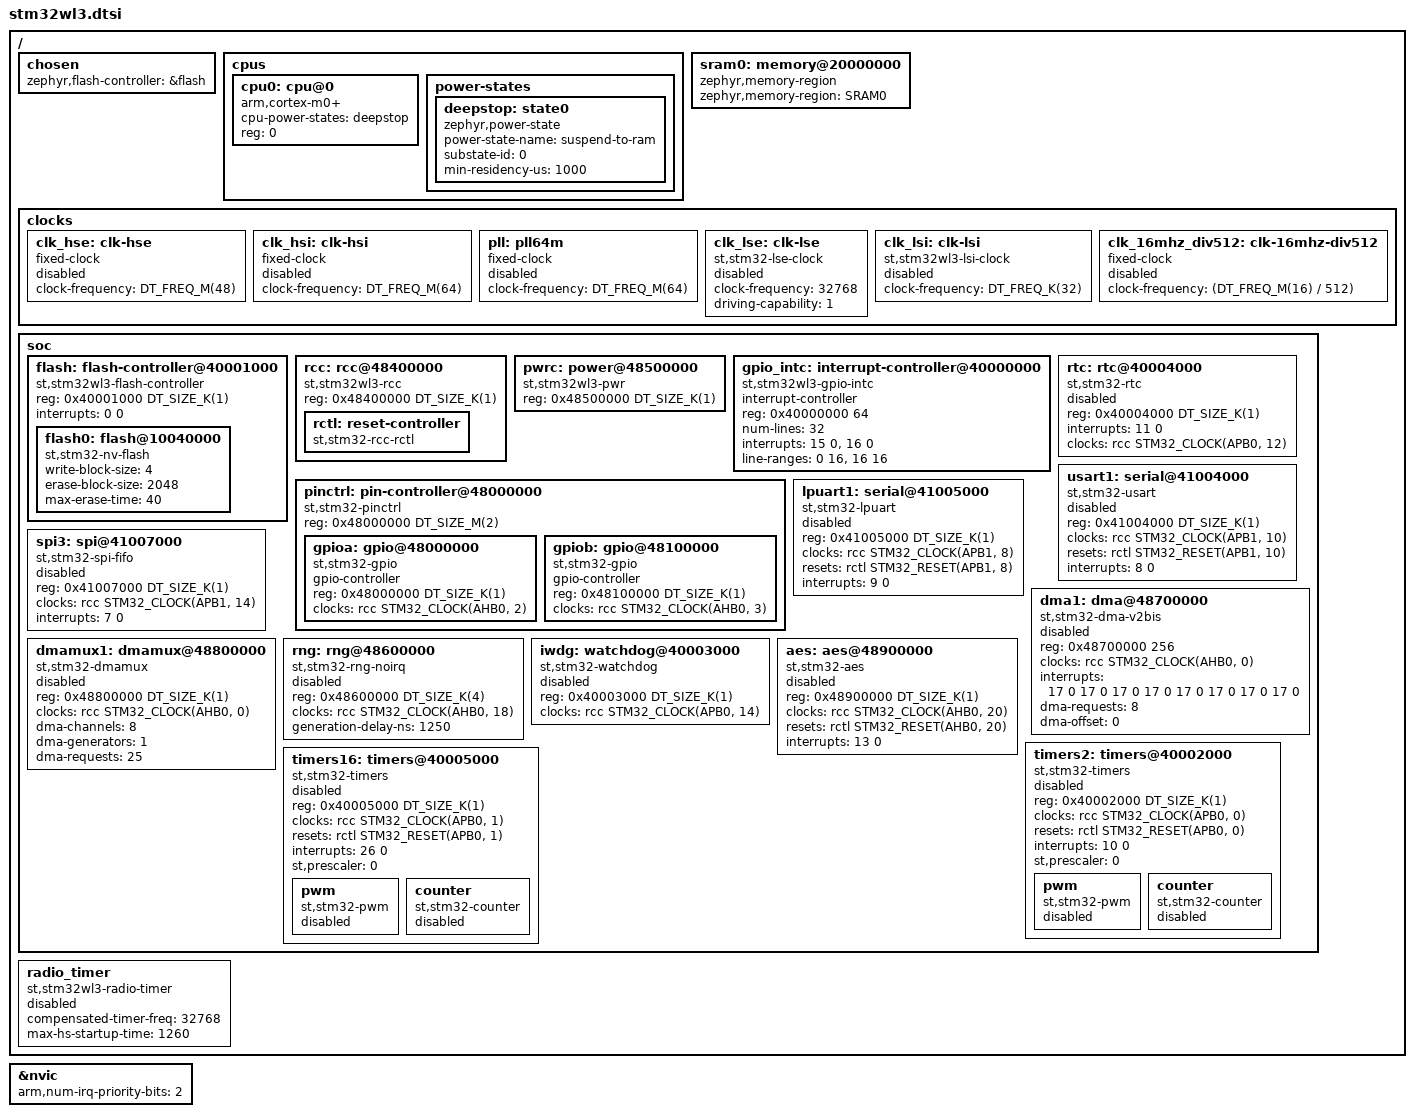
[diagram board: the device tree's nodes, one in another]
/*
 * Copyright (c) 2024 STMicroelectronics
 * Copyright (c) 2026 Movu robotics
 *
 * SPDX-License-Identifier: Apache-2.0
 */

#include <arm/armv6-m.dtsi>
#include <zephyr/dt-bindings/i2c/i2c.h>
#include <zephyr/dt-bindings/adc/adc.h>
#include <zephyr/dt-bindings/pwm/pwm.h>
#include <zephyr/dt-bindings/gpio/gpio.h>
#include <zephyr/dt-bindings/clock/stm32wl3_clock.h>
#include <zephyr/dt-bindings/reset/stm32wl3_reset.h>
#include <zephyr/dt-bindings/dma/stm32_dma.h>
#include <freq.h>
#include <mem.h>

/* NOTE: for some registers, the reserved size in the memory map differs
 * between WL30 and WB31/33. In these cases, if all the registers fit
 * in the smallest size, the peripheral is defined in this file with the
 * smallest size in the 'reg' property.
 */
/ {
	chosen {
		zephyr,flash-controller = &flash;
	};

	cpus {
		#address-cells = <1>;
		#size-cells = <0>;

		cpu0: cpu@0 {
			device_type = "cpu";
			compatible = "arm,cortex-m0+";
			cpu-power-states = <&deepstop>;
			reg = <0>;
		};

		power-states {
			deepstop: state0 {
				compatible = "zephyr,power-state";
				power-state-name = "suspend-to-ram";
				substate-id = <0>;

				/* One millisecond seems reasonable for now. */
				min-residency-us = <1000>;

				/* exit-latency-us property is not needed
				 * since the same concept is applied by the hardware automatically.
				 */
			};
		};
	};

	sram0: memory@20000000 {
		compatible = "zephyr,memory-region", "mmio-sram";
		zephyr,memory-region = "SRAM0";
	};

	clocks {
		/* High-speed clock nodes
		 * These nodes must only be used as input to
		 * the RCC node (i.e., 'clocks' property)
		 */
		clk_hse: clk-hse {
			#clock-cells = <0>;
			compatible = "fixed-clock";
			clock-frequency = <DT_FREQ_M(48)>;
			status = "disabled";
		};

		clk_hsi: clk-hsi {
			#clock-cells = <0>;
			compatible = "fixed-clock";
			clock-frequency = <DT_FREQ_M(64)>;
			status = "disabled";
		};

		/* Dummy node representing the RC64MPLL block in PLL mode
		 * Using this node as RCC node input requires HSE to be enabled.
		 */
		pll: pll64m {
			#clock-cells = <0>;
			compatible = "fixed-clock";
			clock-frequency = <DT_FREQ_M(64)>;
			status = "disabled";
		};

		/* Slow speed clock nodes
		 * These nodes must only be used for the
		 * 'slow-clock' property of the RCC node.
		 */
		clk_lse: clk-lse {
			#clock-cells = <0>;
			compatible = "st,stm32-lse-clock";
			clock-frequency = <32768>;
			driving-capability = <1>;
			status = "disabled";
		};

		clk_lsi: clk-lsi {
			/* "fixed-clock" compatible is required for compatibility with the
			 * macros in `include/drivers/clock_control/stm32_clock_control.h`
			 */
			#clock-cells = <0>;
			compatible = "st,stm32wl3-lsi-clock", "fixed-clock";
			clock-frequency = <DT_FREQ_K(32)>;
			status = "disabled";
		};

		/* Dummy node representing the "CLK_16MHz/512" slow clock source.
		 * WARNING: this clock is not active in DEEPSTOP, so all slow clock peripherals
		 * are stopped, and cannot wake up the SoC, if this is selected as slow-clock!
		 */
		clk_16mhz_div512: clk-16mhz-div512 {
			#clock-cells = <0>;
			compatible = "fixed-clock";
			clock-frequency = <(DT_FREQ_M(16) / 512)>;
			status = "disabled";
		};
	};

	soc {

		flash: flash-controller@40001000 {
			compatible = "st,stm32wl3-flash-controller", "st,stm32-flash-controller";
			reg = <0x40001000 DT_SIZE_K(1)>;
			interrupts = <0 0>;

			#address-cells = <1>;
			#size-cells = <1>;

			flash0: flash@10040000 {
				compatible = "st,stm32-nv-flash", "soc-nv-flash";
				write-block-size = <4>;
				erase-block-size = <2048>;
				/* maximum erase time(ms) for a page (2K) */
				max-erase-time = <40>;
			};
		};

		rcc: rcc@48400000 {
			compatible = "st,stm32wl3-rcc";
			reg = <0x48400000 DT_SIZE_K(1)>;
			#clock-cells = <2>;

			rctl: reset-controller {
				compatible = "st,stm32-rcc-rctl";
				#reset-cells = <1>;
			};
		};

		pwrc: power@48500000 {
			compatible = "st,stm32wl3-pwr";
			reg = <0x48500000 DT_SIZE_K(1)>;
		};

		/* STM32WL3 GPIO interrupt controller
		 *
		 * The 'reg' property corresponds to the SYSCFG memory range,
		 * because that's where the GPIO INTC registers are located.
		 */
		gpio_intc: interrupt-controller@40000000 {
			compatible = "st,stm32wl3-gpio-intc";
			interrupt-controller;
			#interrupt-cells = <1>;
			#address-cells = <1>;
			reg = <0x40000000 64>;
			num-lines = <32>;
			interrupts = <15 0>, <16 0>;
			interrupt-names = "gpioa", "gpiob";
			line-ranges = <0 16>, <16 16>;
		};

		pinctrl: pin-controller@48000000 {
			compatible = "st,stm32-pinctrl";
			#address-cells = <1>;
			#size-cells = <1>;
			reg = <0x48000000 DT_SIZE_M(2)>;

			gpioa: gpio@48000000 {
				compatible = "st,stm32-gpio";
				gpio-controller;
				#gpio-cells = <2>;
				reg = <0x48000000 DT_SIZE_K(1)>;
				clocks = <&rcc STM32_CLOCK(AHB0, 2)>;
			};

			gpiob: gpio@48100000 {
				compatible = "st,stm32-gpio";
				gpio-controller;
				#gpio-cells = <2>;
				reg = <0x48100000 DT_SIZE_K(1)>;
				clocks = <&rcc STM32_CLOCK(AHB0, 3)>;
			};
		};

		rtc: rtc@40004000 {
			compatible = "st,stm32-rtc";
			reg = <0x40004000 DT_SIZE_K(1)>;
			interrupts = <11 0>;
			clocks = <&rcc STM32_CLOCK(APB0, 12)>;
			status = "disabled";
		};

		usart1: serial@41004000 {
			compatible = "st,stm32-usart", "st,stm32-uart";
			reg = <0x41004000 DT_SIZE_K(1)>;

			clocks = <&rcc STM32_CLOCK(APB1, 10)>;
			resets = <&rctl STM32_RESET(APB1, 10)>;
			interrupts = <8 0>;
			status = "disabled";
		};

		lpuart1: serial@41005000 {
			compatible = "st,stm32-lpuart", "st,stm32-uart";
			reg = <0x41005000 DT_SIZE_K(1)>;
			clocks = <&rcc STM32_CLOCK(APB1, 8)>;
			resets = <&rctl STM32_RESET(APB1, 8)>;
			interrupts = <9 0>;
			status = "disabled";
		};

		spi3: spi@41007000 {
			compatible = "st,stm32-spi-fifo", "st,stm32-spi";
			#address-cells = <1>;
			#size-cells = <0>;
			reg = <0x41007000 DT_SIZE_K(1)>;
			clocks = <&rcc STM32_CLOCK(APB1, 14)>;
			interrupts = <7 0>;
			status = "disabled";
		};

		dma1: dma@48700000 {
			compatible = "st,stm32-dma-v2bis";
			#dma-cells = <2>;
			reg = <0x48700000 256>;
			clocks = <&rcc STM32_CLOCK(AHB0, 0)>;
			interrupts = <17 0 17 0 17 0 17 0 17 0 17 0 17 0 17 0>;
			dma-requests = <8>;
			dma-offset = <0>;
			status = "disabled";
		};

		dmamux1: dmamux@48800000 {
			compatible = "st,stm32-dmamux";
			reg = <0x48800000 DT_SIZE_K(1)>;
			/* `clocks` property is identical between DMA and DMAMUX
			 * because they share a single common bit in RCC registers
			 */
			clocks = <&rcc STM32_CLOCK(AHB0, 0)>;
			#dma-cells = <3>;
			dma-channels = <8>;
			dma-generators = <1>;
			dma-requests = <25>;
			status = "disabled";
		};

		rng: rng@48600000 {
			compatible = "st,stm32-rng-noirq";
			reg = <0x48600000 DT_SIZE_K(4)>;
			clocks = <&rcc STM32_CLOCK(AHB0, 18)>;
			generation-delay-ns = <1250>; /* 1.25us */
			status = "disabled";
		};

		iwdg: watchdog@40003000 {
			compatible = "st,stm32-watchdog";
			reg = <0x40003000 DT_SIZE_K(1)>;
			clocks = <&rcc STM32_CLOCK(APB0, 14)>;
			status = "disabled";
		};

		aes: aes@48900000 {
			compatible = "st,stm32-aes";
			reg = <0x48900000 DT_SIZE_K(1)>;
			clocks = <&rcc STM32_CLOCK(AHB0, 20)>;
			resets = <&rctl STM32_RESET(AHB0, 20)>;
			interrupts = <13 0>;
			status = "disabled";
		};

		timers2: timers@40002000 {
			compatible = "st,stm32-timers";
			reg = <0x40002000 DT_SIZE_K(1)>;
			clocks = <&rcc STM32_CLOCK(APB0, 0)>;
			resets = <&rctl STM32_RESET(APB0, 0)>;
			interrupts = <10 0>;
			interrupt-names = "global";
			st,prescaler = <0>;
			status = "disabled";

			pwm {
				compatible = "st,stm32-pwm";
				status = "disabled";
				#pwm-cells = <3>;
			};

			counter {
				compatible = "st,stm32-counter";
				status = "disabled";
			};
		};

		timers16: timers@40005000 {
			compatible = "st,stm32-timers";
			reg = <0x40005000 DT_SIZE_K(1)>;
			clocks = <&rcc STM32_CLOCK(APB0, 1)>;
			resets = <&rctl STM32_RESET(APB0, 1)>;
			interrupts = <26 0>;
			interrupt-names = "global";
			st,prescaler = <0>;
			status = "disabled";

			pwm {
				compatible = "st,stm32-pwm";
				status = "disabled";
				#pwm-cells = <3>;
			};

			counter {
				compatible = "st,stm32-counter";
				status = "disabled";
			};
		};

	};

	radio_timer: radio_timer {
		compatible = "st,stm32wl3-radio-timer";
		compensated-timer-freq = <32768>;
		max-hs-startup-time = <1260>;
		status = "disabled";
	};

};

&nvic {
	arm,num-irq-priority-bits = <2>;
};

